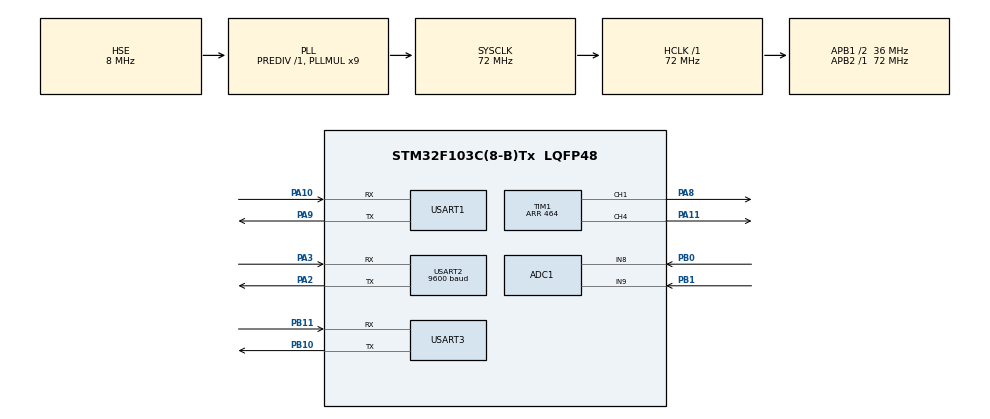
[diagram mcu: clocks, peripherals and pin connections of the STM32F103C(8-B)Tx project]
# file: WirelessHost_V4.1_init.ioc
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ADC1.Channel-0\#ChannelRegularConversion=ADC_CHANNEL_8
ADC1.NbrOfConversionFlag=1
ADC1.Rank-0\#ChannelRegularConversion=1
ADC1.SamplingTime-0\#ChannelRegularConversion=ADC_SAMPLETIME_1CYCLE_5
ADC1.master=1
Dma.Request0=USART1_TX
Dma.Request1=USART2_RX
Dma.Request2=USART2_TX
Dma.Request3=USART3_RX
Dma.Request4=USART3_TX
Dma.USART1_TX.0.Direction=DMA_MEMORY_TO_PERIPH
Dma.USART1_TX.0.Instance=DMA1_Channel4
Dma.USART1_TX.0.MemDataAlignment=DMA_MDATAALIGN_BYTE
Dma.USART1_TX.0.MemInc=DMA_MINC_ENABLE
Dma.USART1_TX.0.Mode=DMA_NORMAL
Dma.USART1_TX.0.PeriphDataAlignment=DMA_PDATAALIGN_BYTE
Dma.USART1_TX.0.PeriphInc=DMA_PINC_DISABLE
Dma.USART1_TX.0.Priority=DMA_PRIORITY_LOW
Dma.USART2_RX.1.Direction=DMA_PERIPH_TO_MEMORY
Dma.USART2_RX.1.Instance=DMA1_Channel6
Dma.USART2_RX.1.MemDataAlignment=DMA_MDATAALIGN_BYTE
Dma.USART2_RX.1.MemInc=DMA_MINC_ENABLE
Dma.USART2_RX.1.Mode=DMA_NORMAL
Dma.USART2_RX.1.PeriphDataAlignment=DMA_PDATAALIGN_BYTE
Dma.USART2_RX.1.PeriphInc=DMA_PINC_DISABLE
Dma.USART2_RX.1.Priority=DMA_PRIORITY_LOW
Dma.USART2_TX.2.Direction=DMA_MEMORY_TO_PERIPH
Dma.USART2_TX.2.Instance=DMA1_Channel7
Dma.USART2_TX.2.MemDataAlignment=DMA_MDATAALIGN_BYTE
Dma.USART2_TX.2.MemInc=DMA_MINC_ENABLE
Dma.USART2_TX.2.Mode=DMA_NORMAL
Dma.USART2_TX.2.PeriphDataAlignment=DMA_PDATAALIGN_BYTE
Dma.USART2_TX.2.PeriphInc=DMA_PINC_DISABLE
Dma.USART2_TX.2.Priority=DMA_PRIORITY_LOW
Dma.USART3_RX.3.Direction=DMA_PERIPH_TO_MEMORY
Dma.USART3_RX.3.Instance=DMA1_Channel3
Dma.USART3_RX.3.MemDataAlignment=DMA_MDATAALIGN_BYTE
Dma.USART3_RX.3.MemInc=DMA_MINC_ENABLE
Dma.USART3_RX.3.Mode=DMA_NORMAL
Dma.USART3_RX.3.PeriphDataAlignment=DMA_PDATAALIGN_BYTE
Dma.USART3_RX.3.PeriphInc=DMA_PINC_DISABLE
Dma.USART3_RX.3.Priority=DMA_PRIORITY_LOW
Dma.USART3_TX.4.Direction=DMA_MEMORY_TO_PERIPH
Dma.USART3_TX.4.Instance=DMA1_Channel2
Dma.USART3_TX.4.MemDataAlignment=DMA_MDATAALIGN_BYTE
Dma.USART3_TX.4.MemInc=DMA_MINC_ENABLE
Dma.USART3_TX.4.Mode=DMA_NORMAL
Dma.USART3_TX.4.PeriphDataAlignment=DMA_PDATAALIGN_BYTE
Dma.USART3_TX.4.PeriphInc=DMA_PINC_DISABLE
Dma.USART3_TX.4.Priority=DMA_PRIORITY_LOW
Mcu.Family=STM32F1
Mcu.Name=STM32F103C(8-B)Tx
Mcu.Package=LQFP48
NVIC.DMA1_Channel2_IRQn=true\:0\:0\:false\:false\:true\:true\:true\:true
NVIC.DMA1_Channel3_IRQn=true\:0\:0\:false\:false\:true\:true\:true\:true
NVIC.DMA1_Channel4_IRQn=true\:3\:3\:true\:false\:true\:true\:true\:true
NVIC.DMA1_Channel6_IRQn=true\:0\:0\:false\:false\:true\:true\:true\:true
NVIC.DMA1_Channel7_IRQn=true\:0\:0\:false\:false\:true\:true\:true\:true
NVIC.PriorityGroup=NVIC_PRIORITYGROUP_2
NVIC.USART2_IRQn=true\:0\:0\:false\:false\:true\:true\:true\:true
NVIC.USART3_IRQn=true\:0\:0\:false\:false\:true\:true\:true\:true
PA10.Mode=Asynchronous
PA10.Signal=USART1_RX
PA11.Signal=S_TIM1_CH4
PA13.Mode=JTAG_4_pins
PA13.Signal=SYS_JTMS-SWDIO
PA14.Mode=JTAG_4_pins
PA14.Signal=SYS_JTCK-SWCLK
PA15.Mode=JTAG_4_pins
PA15.Signal=SYS_JTDI
PA2.Mode=Asynchronous
PA2.Signal=USART2_TX
PA3.Mode=Asynchronous
PA3.Signal=USART2_RX
PA8.Signal=S_TIM1_CH1
PA9.Mode=Asynchronous
PA9.Signal=USART1_TX
PB0.Signal=ADCx_IN8
PB1.Signal=ADCx_IN9
PB10.Mode=Asynchronous
PB10.Signal=USART3_TX
PB11.Mode=Asynchronous
PB11.Signal=USART3_RX
PB3.Mode=JTAG_4_pins
PB3.Signal=SYS_JTDO-TRACESWO
PD0-OSC_IN.Mode=HSE-External-Oscillator
PD0-OSC_IN.Signal=RCC_OSC_IN
PD1-OSC_OUT.Mode=HSE-External-Oscillator
PD1-OSC_OUT.Signal=RCC_OSC_OUT
ProjectManager.HeapSize=0x200
ProjectManager.StackSize=0x400
ProjectManager.TargetToolchain=STM32CubeIDE
RCC.ADCPresc=RCC_ADCPCLK2_DIV8
RCC.AHBFreq_Value=72000000
RCC.APB1CLKDivider=RCC_HCLK_DIV2
RCC.APB1Freq_Value=36000000
RCC.APB1TimFreq_Value=72000000
RCC.APB2Freq_Value=72000000
RCC.APB2TimFreq_Value=72000000
RCC.HCLKFreq_Value=72000000
RCC.PLLMUL=RCC_PLL_MUL9
RCC.PLLSourceVirtual=RCC_PLLSOURCE_HSE
RCC.SYSCLKFreq_VALUE=72000000
RCC.SYSCLKSource=RCC_SYSCLKSOURCE_PLLCLK
RCC.USBFreq_Value=72000000
SH.ADCx_IN8.0=ADC1_IN8,IN8
SH.ADCx_IN9.0=ADC1_IN9,IN9
SH.S_TIM1_CH1.0=TIM1_CH1,PWM Generation1 CH1
SH.S_TIM1_CH4.0=TIM1_CH4,PWM Generation4 CH4
TIM1.AutoReloadPreload=TIM_AUTORELOAD_PRELOAD_ENABLE
TIM1.AutomaticOutput=TIM_AUTOMATICOUTPUT_ENABLE
TIM1.Channel-PWM\ Generation1\ CH1=TIM_CHANNEL_1
TIM1.Channel-PWM\ Generation4\ CH4=TIM_CHANNEL_4
TIM1.ClockDivision=TIM_CLOCKDIVISION_DIV1
TIM1.OCMode_PWM-PWM\ Generation4\ CH4=TIM_OCMODE_PWM2
TIM1.Period=464
TIM1.Pulse-PWM\ Generation1\ CH1=232
TIM1.Pulse-PWM\ Generation4\ CH4=232
USART1.VirtualMode=VM_ASYNC
USART2.BaudRate=9600
USART2.VirtualMode=VM_ASYNC
USART3.VirtualMode=VM_ASYNC
VP_TIM1_VS_ClockSourceINT.Mode=Internal
board=custom

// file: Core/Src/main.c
  /* USER CODE BEGIN Header */
/**
  ******************************************************************************
  * @file           : main.c
  * @brief          : Main program body
  ******************************************************************************
  * @attention
  *
  * Copyright (c) 2024 STMicroelectronics.
  * All rights reserved.
  *
  * This software is licensed under terms that can be found in the LICENSE file
  * in the root directory of this software component.
  * If no LICENSE file comes with this software, it is provided AS-IS.
  *
  ******************************************************************************
  */
/* USER CODE END Header */
#include "main.h"
#include "adc.h"
#include "dma.h"
#include "tim.h"
#include "usart.h"
#include "gpio.h"

/* USER CODE BEGIN Includes */
#include "timer.h"
/* USER CODE END Includes */

void SystemClock_Config(void);

/* USER CODE BEGIN 0 */
uint8_t data[8] = {0x12, 0x34, 0x56, 0x78, 0x9A, 0xBC, 0xDE, 0xF0};
/* USER CODE END 0 */

int main(void)
{

  /* USER CODE BEGIN 1 */
//	 uint8_t data[20] = {0xAA, 0xAA, 0xAA,0xAA, 0xAA, 0xAA,0xAA, 0xAA, 0xAA,0xAA, 0xAA, 0xAA,0xAA, 0xAA, 0xAA,0xAA, 0xAA, 0xAA, 0x0D, 0x0A};
  /* USER CODE END 1 */

  /* MCU Configuration--------------------------------------------------------*/

  /* Reset of all peripherals, Initializes the Flash interface and the Systick. */
  HAL_Init();

  /* Configure the system clock */
  SystemClock_Config();

  /* Initialize all configured peripherals */
  MX_GPIO_Init();
  MX_DMA_Init();
  MX_ADC1_Init();
  MX_TIM1_Init();
  MX_USART1_UART_Init();
  MX_USART2_UART_Init();
  MX_USART3_UART_Init();
  /* USER CODE BEGIN 2 */
  HAL_TIM_PWM_Start(&htim1, TIM_CHANNEL_1);
  HAL_TIM_PWM_Start(&htim1, TIM_CHANNEL_4);
  change_out_frequence(160000);//改变输出频率
//  bpm_init();
//  bpm_receive();
  /* USER CODE END 2 */

  /* Infinite loop */
  /* USER CODE BEGIN WHILE */
  HAL_UARTEx_ReceiveToIdle_DMA(&huart2,usart2_rx_buffer,BUF_SIZE);
  HAL_UARTEx_ReceiveToIdle_DMA(&huart3,usart3_rx_buffer,BUF_SIZE);
  while (1)
  {
	HAL_Delay(200);
    /* USER CODE END WHILE */

    /* USER CODE BEGIN 3 */
//	HAL_UART_Transmit(&huart1, &data[0], 5,1000) ;
//	HAL_Delay(50);
//	HAL_UART_Transmit_DMA(&huart2, &data[0], 8) ;
//	HAL_Delay(500);
  }
  /* USER CODE END 3 */
}

void SystemClock_Config(void)
{
  RCC_OscInitTypeDef RCC_OscInitStruct = {0};
  RCC_ClkInitTypeDef RCC_ClkInitStruct = {0};
  RCC_PeriphCLKInitTypeDef PeriphClkInit = {0};

  /** Initializes the RCC Oscillators according to the specified parameters
  * in the RCC_OscInitTypeDef structure.
  */
  RCC_OscInitStruct.OscillatorType = RCC_OSCILLATORTYPE_HSE;
  RCC_OscInitStruct.HSEState = RCC_HSE_ON;
  RCC_OscInitStruct.HSEPredivValue = RCC_HSE_PREDIV_DIV1;
  RCC_OscInitStruct.HSIState = RCC_HSI_ON;
  RCC_OscInitStruct.PLL.PLLState = RCC_PLL_ON;
  RCC_OscInitStruct.PLL.PLLSource = RCC_PLLSOURCE_HSE;
  RCC_OscInitStruct.PLL.PLLMUL = RCC_PLL_MUL9;
  if (HAL_RCC_OscConfig(&RCC_OscInitStruct) != HAL_OK)
  {
    Error_Handler();
  }

  /** Initializes the CPU, AHB and APB buses clocks
  */
  RCC_ClkInitStruct.ClockType = RCC_CLOCKTYPE_HCLK|RCC_CLOCKTYPE_SYSCLK
                              |RCC_CLOCKTYPE_PCLK1|RCC_CLOCKTYPE_PCLK2;
  RCC_ClkInitStruct.SYSCLKSource = RCC_SYSCLKSOURCE_PLLCLK;
  RCC_ClkInitStruct.AHBCLKDivider = RCC_SYSCLK_DIV1;
  RCC_ClkInitStruct.APB1CLKDivider = RCC_HCLK_DIV2;
  RCC_ClkInitStruct.APB2CLKDivider = RCC_HCLK_DIV1;

  if (HAL_RCC_ClockConfig(&RCC_ClkInitStruct, FLASH_LATENCY_2) != HAL_OK)
  {
    Error_Handler();
  }
  PeriphClkInit.PeriphClockSelection = RCC_PERIPHCLK_ADC;
  PeriphClkInit.AdcClockSelection = RCC_ADCPCLK2_DIV8;
  if (HAL_RCCEx_PeriphCLKConfig(&PeriphClkInit) != HAL_OK)
  {
    Error_Handler();
  }
}

void Error_Handler(void)
{
  __disable_irq();
  while (1)
  {
  }
}
